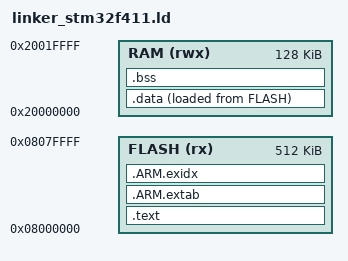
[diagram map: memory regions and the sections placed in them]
ENTRY(Reset_Handler)

MEMORY
{
    FLASH (rx)  : ORIGIN = 0x08000000, LENGTH = 512K
    RAM   (rwx) : ORIGIN = 0x20000000, LENGTH = 128K
}

_estack = ORIGIN(RAM) + LENGTH(RAM);

SECTIONS
{
    .text :
    {
        . = ALIGN(4);

        KEEP(*(.isr_vector))

        . = ALIGN(4);
        *(.text*)

        . = ALIGN(4);
        *(.rodata*)

        . = ALIGN(4);
        _etext = .;

    } > FLASH

    /* Unwind metadata may be pulled in by libgcc (e.g. 64-bit division). */
    .ARM.extab :
    {
        . = ALIGN(4);
        *(.ARM.extab* .gnu.linkonce.armextab.*)
    } > FLASH

    .ARM.exidx :
    {
        . = ALIGN(4);
        __exidx_start = .;
        *(.ARM.exidx* .gnu.linkonce.armexidx.*)
        __exidx_end = .;
    } > FLASH

    .data :
    {
        . = ALIGN(4);

        _sdata = .;

        *(.data*)

        . = ALIGN(4);

        _edata = .;

    } > RAM AT> FLASH

    /* Startup copies initialized data from its actual Flash load address. */
    _sidata = LOADADDR(.data);

    .bss (NOLOAD) :
    {
        . = ALIGN(4);

        _sbss = .;

        *(.bss*)
        *(COMMON)

        . = ALIGN(4);

        _ebss = .;

    } > RAM

    .ARM.attributes 0 :
    {
        *(.ARM.attributes)
    }
}
